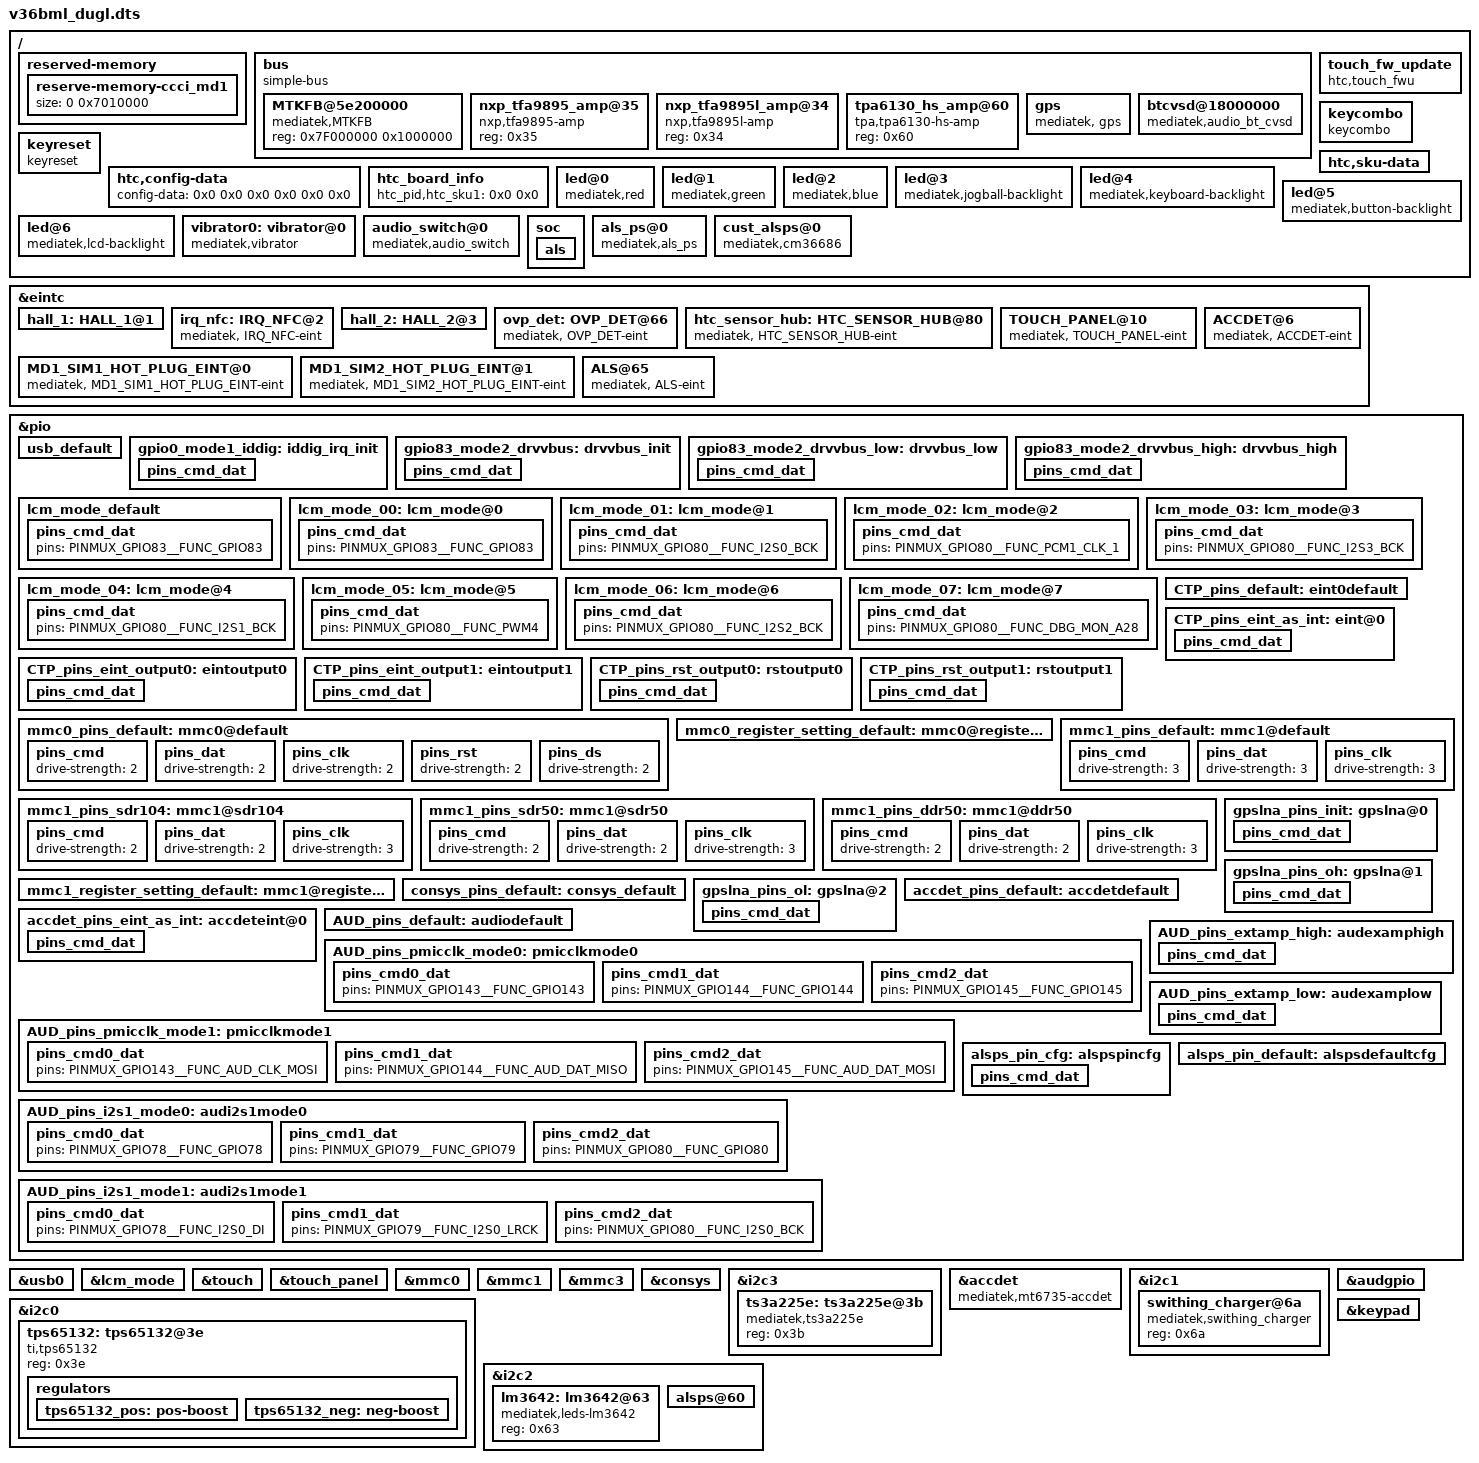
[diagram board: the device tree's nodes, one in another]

/dts-v1/;

#include "mt6753.dtsi"
#include "dt-bindings/lcm/hx8394f_hd720_dsi_vdo_truly_v36.dtsi"
/* see below #include "cust.dtsi" */

/ {
	reserved-memory {
                reserve-memory-ccci_md1 {
                        size = <0 0x7010000>;
                };
	};
        bus {
                compatible = "simple-bus";
                #address-cells = <1>;
                #size-cells = <1>;
                ranges = <0 0 0 0xffffffff>;

                MTKFB@5e200000 {
                        compatible = "mediatek,MTKFB";
                        reg = <0x7F000000 0x1000000>;
                };
                nxp_tfa9895_amp@35 {
                        compatible = "nxp,tfa9895-amp";
                        reg = <0x35>;
                };
                nxp_tfa9895l_amp@34 {
                        compatible = "nxp,tfa9895l-amp";
                        reg = <0x34>;
                };
                tpa6130_hs_amp@60 {
                        compatible = "tpa,tpa6130-hs-amp";
                        reg = <0x60>;
                };
        };
        touch_fw_update: touch_fw_update {
                compatible = "htc,touch_fwu";
        };
        keycombo {
                compatible = "keycombo";
                clr_gpio = <0x3a>;
                key_down_delay = <0x0>;
                keys_down = <0x74 0x0>;
                keys_up = <0x73 0x0>;
        };

        keyreset {
                compatible = "keyreset";
                key_down_delay = <0x2328>;
                keys_down = <0x74 0x73 0x0>;
        };
        htc,config-data {
/*        <debugflag kernelflag bootloaderflag radioflag radioflag_ex1 radioflag_ex2> */
                config-data = <0x0 0x0 0x0 0x0 0x0 0x0>;
        };

        htc,sku-data {
                sku-data = <0x0 0x0 0x0 0x0 0x0 0x0 0x0 0x0 0x0 0x0 0x0 0x0>;
        };
        htc_board_info:htc_board_info {
                htc_pid,htc_sku1 = <0x0 0x0>;
        };
/*
        ovp_det: ovp_det { };
        irq_nfc: irq_nfc { };
*/
        led@0 {
               compatible = "mediatek,red";
               led_mode = <0x0>;
               data = <0x1>;
               pwm_config = <0x0 0x0 0x0 0x0 0x0>;
        };

        led@1 {
               compatible = "mediatek,green";
               led_mode = <0x0>;
               data = <0x1>;
               pwm_config = <0x0 0x0 0x0 0x0 0x0>;
        };

        led@2 {
               compatible = "mediatek,blue";
               led_mode = <0x0>;
               data = <0x1>;
               pwm_config = <0x0 0x0 0x0 0x0 0x0>;
        };

        led@3 {
               compatible = "mediatek,jogball-backlight";
              led_mode = <0x0>;
               data = <0x1>;
             pwm_config = <0x0 0x0 0x0 0x0 0x0>;
        };

        led@4 {
               compatible = "mediatek,keyboard-backlight";
               led_mode = <0x0>;
               data = <0x1>;
               pwm_config = <0x0 0x0 0x0 0x0 0x0>;
        };

        led@5 {
               compatible = "mediatek,button-backlight";
               led_mode = <0x0>;
               data = <0x1>;
               pwm_config = <0x0 0x0 0x0 0x0 0x0>;
        };

        led@6 {
               compatible = "mediatek,lcd-backlight";
               led_mode = <0x5>;
               data = <0x1>;
               pwm_config = <0x0 0x0 0x0 0x0 0x0>;
        };
        vibrator0:vibrator@0 {
                compatible = "mediatek,vibrator";
                vib_timer = <25>;
                vib_limit = <9>;
                vib_vol= <5>;
        };
};
&eintc {
        hall_1: HALL_1@1 { };
        irq_nfc: IRQ_NFC@2 {
                                compatible = "mediatek, IRQ_NFC-eint";
                                interrupt-parent = <&eintc>;
                                interrupts = <0x2 0x4>;
                                debounce = <0x2 0x0>;
	};
        hall_2: HALL_2@3 { };
        ovp_det: OVP_DET@66 {
                                compatible = "mediatek, OVP_DET-eint";
                                interrupt-parent = <&eintc>;
                                interrupts = <0x42 0x8>;
                                debounce = <0x42 0x0>;
	 };
        htc_sensor_hub: HTC_SENSOR_HUB@80 { };
};
#include "cust.dtsi"

/* USB GPIO Kernal Standardization start */
&pio {
        usb_default: usb_default {
        };

        gpio0_mode1_iddig: iddig_irq_init {
                pins_cmd_dat {
                        pins = <PINMUX_GPIO0__FUNC_IDDIG>;
                        slew-rate = <0>;
                        bias-pull-up = <00>;
                };
        };

        gpio83_mode2_drvvbus: drvvbus_init {
                pins_cmd_dat {
                        pins = <PINMUX_GPIO83__FUNC_GPIO83>;
                        slew-rate = <1>;
                        bias-pull-up = <00>;
                };
        };

        gpio83_mode2_drvvbus_low: drvvbus_low {
                pins_cmd_dat {
                        pins = <PINMUX_GPIO83__FUNC_GPIO83>;
                        slew-rate = <1>;
                        output-low;
                        bias-pull-down = <00>;
                };
        };

        gpio83_mode2_drvvbus_high: drvvbus_high {
                pins_cmd_dat {
                        pins = <PINMUX_GPIO83__FUNC_GPIO83>;
                        slew-rate = <1>;
                        output-high;
                        bias-pull-down = <00>;
                };
        };
};

&usb0 {
        iddig_gpio = <0 1>;
        pinctrl-names = "default", "iddig_irq_init", "drvvbus_init", "drvvbus_low", "drvvbus_high";
        pinctrl-0 = <&usb_default>; /* 0x75 */
        pinctrl-1 = <&gpio0_mode1_iddig>; /* 0x76 */
        pinctrl-2 = <&gpio83_mode2_drvvbus>; /* 0x77 */
        pinctrl-3 = <&gpio83_mode2_drvvbus_low>; /* 0x78 */
        pinctrl-4 = <&gpio83_mode2_drvvbus_high>; /* 0x79 */
        status = "okay";
};
/* USB GPIO Kernal Standardization end */

/* LCM GPIO Kernal Standardization start */
&pio {
        lcm_mode_default: lcm_mode_default {
                pins_cmd_dat {
                        pins = <PINMUX_GPIO83__FUNC_GPIO83>;
                };
        };

        lcm_mode_00: lcm_mode@0 {
                pins_cmd_dat {
                        pins = <PINMUX_GPIO83__FUNC_GPIO83>;
                };
        };

        lcm_mode_01: lcm_mode@1 {
                pins_cmd_dat {
                        pins = <PINMUX_GPIO80__FUNC_I2S0_BCK>;
                };
        };

        lcm_mode_02: lcm_mode@2 {
                pins_cmd_dat {
                        pins = <PINMUX_GPIO80__FUNC_PCM1_CLK_1>;
                };
        };

        lcm_mode_03: lcm_mode@3 {
                pins_cmd_dat {
                        pins = <PINMUX_GPIO80__FUNC_I2S3_BCK>;
                };
        };

        lcm_mode_04: lcm_mode@4 {
                pins_cmd_dat {
                        pins = <PINMUX_GPIO80__FUNC_I2S1_BCK>;
                };
        };

        lcm_mode_05: lcm_mode@5 {
                pins_cmd_dat {
                        pins = <PINMUX_GPIO80__FUNC_PWM4>;
                };
        };

        lcm_mode_06: lcm_mode@6 {
                pins_cmd_dat {
                        pins = <PINMUX_GPIO80__FUNC_I2S2_BCK>;
                };
        };

        lcm_mode_07: lcm_mode@7 {
                pins_cmd_dat {
                        pins = <PINMUX_GPIO80__FUNC_DBG_MON_A28>;
                };
	};
};

&lcm_mode {
        pinctrl-names = "default", "lcm_mode_00", "lcm_mode_01", "lcm_mode_02", "lcm_mode_03", "lcm_mode_04",
         "lcm_mode_05", "lcm_mode_06", "lcm_mode_07";
        pinctrl-0 = <&lcm_mode_default>;
        pinctrl-1 = <&lcm_mode_00>;
        pinctrl-2 = <&lcm_mode_01>;
        pinctrl-3 = <&lcm_mode_02>;
        pinctrl-4 = <&lcm_mode_03>;
        pinctrl-5 = <&lcm_mode_04>;
        pinctrl-6 = <&lcm_mode_05>;
        pinctrl-7 = <&lcm_mode_06>;
        pinctrl-8 = <&lcm_mode_07>;
        lcm_power_gpio = <&pio 83 0>;
        lcm_bl_gpio = <&pio 86 0>;
        status = "okay";
};
/* LCM GPIO Kernal Standardization end */

/* TOUCH start */
&touch {
        tpd-resolution = <720 1280>;
        use-tpd-button = <0>;
        tpd-key-num = <3>;
        tpd-key-local= <139 172 158 0>;
        tpd-key-dim-local = <90 883 100 40 230 883 100 40 370 883 100 40 0 0 0 0>;
        tpd-max-touch-num = <5>;
        tpd-filter-enable = <1>;
        tpd-filter-pixel-density = <320>;
        tpd-filter-custom-prameters = <0 0 0 0 0 0 0 0 0 0 0 0>;
        tpd-filter-custom-speed = <0 0 0>;
        pinctrl-names = "default", "state_eint_as_int", "state_eint_output0", "state_eint_output1",
                "state_rst_output0", "state_rst_output1";
        pinctrl-0 = <&CTP_pins_default>;
        pinctrl-1 = <&CTP_pins_eint_as_int>;
        pinctrl-2 = <&CTP_pins_eint_output0>;
        pinctrl-3 = <&CTP_pins_eint_output1>;
        pinctrl-4 = <&CTP_pins_rst_output0>;
        pinctrl-5 = <&CTP_pins_rst_output1>;
        status = "okay";
};

&pio {
        CTP_pins_default: eint0default {
        };
        CTP_pins_eint_as_int: eint@0 {
                pins_cmd_dat {
                        pins = <PINMUX_GPIO10__FUNC_GPIO10>;
                        slew-rate = <0>;
                        bias-disable;
                };
        };
        CTP_pins_eint_output0: eintoutput0 {
                pins_cmd_dat {
                        pins = <PINMUX_GPIO10__FUNC_GPIO10>;
                        slew-rate = <1>;
                        output-low;
                };
        };
        CTP_pins_eint_output1: eintoutput1 {
                pins_cmd_dat {
                        pins = <PINMUX_GPIO10__FUNC_GPIO10>;
                        slew-rate = <1>;
                        output-high;
                };
        };
        CTP_pins_rst_output0: rstoutput0 {
                pins_cmd_dat {
                        pins = <PINMUX_GPIO62__FUNC_GPIO62>;
                        slew-rate = <1>;
                        output-low;
                };
        };
        CTP_pins_rst_output1: rstoutput1 {
                pins_cmd_dat {
                        pins = <PINMUX_GPIO62__FUNC_GPIO62>;
                        slew-rate = <1>;
                        output-high;
                };
        };
};
&touch_panel {
        interrupt-parent = <&eintc>;
        interrupts = <0xa 0x2>;
        debounce = <0xa 0x0>;
};
&eintc {
                        TOUCH_PANEL@10 {
                                compatible = "mediatek, TOUCH_PANEL-eint";
                                interrupt-parent = <&eintc>;
                                interrupts = <0xa 0x2>;
                                debounce = <0xa 0x0>;
                        };
};
/* TOUCH end */
/* mmc start */
&mmc0 {
                clk_src = /bits/ 8 <MSDC50_CLKSRC_400MHZ>;
                bus-width = <8>;
                max-frequency = <200000000>;
                cap-mmc-highspeed;
                msdc-sys-suspend;
                mmc-ddr-1_8v;
                mmc-hs200-1_8v;
                mmc-hs400-1_8v;
                non-removable;
                pinctl = <&mmc0_pins_default>;
                register_setting = <&mmc0_register_setting_default>;
                host_function = /bits/ 8 <MSDC_EMMC>;
                bootable;
                status = "okay";
};

&mmc1 {
                clk_src = /bits/ 8 <MSDC30_CLKSRC_200MHZ>;
                bus-width = <4>;
                max-frequency = <200000000>;
                msdc-sys-suspend;
                cap-sd-highspeed;
                sd-uhs-sdr12;
                sd-uhs-sdr25;
                sd-uhs-sdr50;
                sd-uhs-sdr104;
                sd-uhs-ddr50;
                pinctl = <&mmc1_pins_default>;
                pinctl_sdr104 = <&mmc1_pins_sdr104>;
                pinctl_sdr50 = <&mmc1_pins_sdr50>;
                pinctl_ddr50 = <&mmc1_pins_ddr50>;
                register_setting = <&mmc1_register_setting_default>;
                host_function = /bits/ 8 <MSDC_SD>;
                cd_level = /bits/ 8 <MSDC_CD_LOW>;
                cd-gpios = <&pio 5 0>;
                status = "okay";
};

&mmc3 {
                clk_src = /bits/ 8 <MSDC30_CLKSRC_200MHZ>;
                bus-width = <4>;
                max-frequency = <50000000>;
                cap-sd-highspeed;
                sd-uhs-sdr12;
                sd-uhs-sdr25;
                sd-uhs-sdr50;
                host_function = /bits/ 8 <MSDC_SDIO>;
                non-removable;
                status = "okay";
};

&pio {
        mmc0_pins_default: mmc0@default {
                        pins_cmd {
                                drive-strength = /bits/ 8 <2>;
                        };
                        pins_dat {
                                drive-strength = /bits/ 8 <2>;
                        };
                        pins_clk {
                                drive-strength = /bits/ 8 <2>;
                        };
                        pins_rst {
                                drive-strength = /bits/ 8 <2>;
                        };
                        pins_ds {
                                drive-strength = /bits/ 8 <2>;
                        };
        };

        mmc0_register_setting_default: mmc0@register_default {
                dat0rddly      = /bits/ 8 <0>;
                dat1rddly      = /bits/ 8 <0>;
                dat2rddly      = /bits/ 8 <0>;
                dat3rddly      = /bits/ 8 <0>;
                dat4rddly      = /bits/ 8 <0>;
                dat5rddly      = /bits/ 8 <0>;
                dat6rddly      = /bits/ 8 <0>;
                dat7rddly      = /bits/ 8 <0>;
                datwrddly      = /bits/ 8 <0>;
                cmdrrddly      = /bits/ 8 <0>;
                cmdrddly       = /bits/ 8 <0>;
                cmd_edge = /bits/ 8 <MSDC_SMPL_FALLING>;
                rdata_edge = /bits/ 8 <MSDC_SMPL_FALLING>;
                wdata_edge = /bits/ 8 <MSDC_SMPL_FALLING>;

                ett-hs200-cells = <12>;
                ett-hs200-default = <OFFSET_MSDC_PATCH_BIT0     MSDC_PB0_INT_DAT_LATCH_CK_SEL 0x0
                        OFFSET_MSDC_PATCH_BIT0  MSDC_PB0_CKGEN_MSDC_DLY_SEL   0x0
                        OFFSET_MSDC_PATCH_BIT1  MSDC_PB1_CMD_RSP_TA_CNTR      0x1
                        OFFSET_MSDC_IOCON               MSDC_IOCON_RSPL               0x1
                        OFFSET_MSDC_PAD_TUNE0   MSDC_PAD_TUNE0_CMDRDLY        0xf
                        OFFSET_MSDC_PAD_TUNE0   MSDC_PAD_TUNE0_CMDRRDLY       0x0
                        OFFSET_MSDC_PATCH_BIT1          MSDC_PB1_WRDAT_CRCS_TA_CNTR   0x1
                        OFFSET_MSDC_PAD_TUNE0   MSDC_PAD_TUNE0_DATWRDLY       0xf
                        OFFSET_MSDC_IOCON                       MSDC_IOCON_W_D0SPL            0x1
                        OFFSET_MSDC_DAT_RDDLY0          MSDC_DAT_RDDLY0_D0            0xf
                        OFFSET_MSDC_PAD_TUNE0   MSDC_PAD_TUNE0_DATRRDLY       0x16
                        OFFSET_MSDC_IOCON               MSDC_IOCON_R_D_SMPL           0x0>;

                ett-hs400-cells = <8>;
                ett-hs400-default = <OFFSET_MSDC_PATCH_BIT0     MSDC_PB0_INT_DAT_LATCH_CK_SEL   0x0
                        OFFSET_MSDC_PATCH_BIT0          MSDC_PB0_CKGEN_MSDC_DLY_SEL             0x0
                        OFFSET_EMMC50_PAD_DS_TUNE       MSDC_EMMC50_PAD_DS_TUNE_DLY1    0x2
                        OFFSET_EMMC50_PAD_DS_TUNE       MSDC_EMMC50_PAD_DS_TUNE_DLY3    0xe
                        OFFSET_MSDC_PATCH_BIT1                  MSDC_PB1_CMD_RSP_TA_CNTR        0x1
                        OFFSET_MSDC_IOCON               MSDC_IOCON_RSPL                         0x0
                        OFFSET_MSDC_PAD_TUNE0                   MSDC_PAD_TUNE0_CMDRDLY          0xf
                        OFFSET_MSDC_PAD_TUNE0           MSDC_PAD_TUNE0_CMDRRDLY         0xd>;
        };

        mmc1_pins_default: mmc1@default {
                        pins_cmd {
                                drive-strength = /bits/ 8 <3>;
                        };
                        pins_dat {
                                drive-strength = /bits/ 8 <3>;
                        };
                        pins_clk {
                                drive-strength = /bits/ 8 <3>;
                        };
        };

        mmc1_pins_sdr104: mmc1@sdr104 {
                        pins_cmd {
                                drive-strength = /bits/ 8 <2>;
                        };
                        pins_dat {
                                drive-strength = /bits/ 8 <2>;
                        };
                        pins_clk {
                                drive-strength = /bits/ 8 <3>;
                        };
        };

        mmc1_pins_sdr50: mmc1@sdr50 {
                        pins_cmd {
                                drive-strength = /bits/ 8 <2>;
                        };
                        pins_dat {
                                drive-strength = /bits/ 8 <2>;
                        };
                        pins_clk {
                                drive-strength = /bits/ 8 <3>;
                        };
        };

        mmc1_pins_ddr50: mmc1@ddr50 {
                        pins_cmd {
                                drive-strength = /bits/ 8 <2>;
                        };
                        pins_dat {
                                drive-strength = /bits/ 8 <2>;
                        };
                        pins_clk {
                                drive-strength = /bits/ 8 <3>;
                        };
        };

        mmc1_register_setting_default: mmc1@register_default {
                                dat0rddly      = /bits/ 8 <0>;
                                dat1rddly      = /bits/ 8 <0>;
                                dat2rddly      = /bits/ 8 <0>;
                                dat3rddly      = /bits/ 8 <0>;
                                datwrddly      = /bits/ 8 <0>;
                                cmdrrddly      = /bits/ 8 <0>;
                                cmdrddly       = /bits/ 8 <0>;
                                cmd_edge = /bits/ 8 <MSDC_SMPL_FALLING>;
                                rdata_edge = /bits/ 8 <MSDC_SMPL_FALLING>;
                                wdata_edge = /bits/ 8 <MSDC_SMPL_FALLING>;
        };
};
/* mmc end */

/* CONSYS GPIO standardization */
&pio {
        consys_pins_default: consys_default {

        };

        gpslna_pins_init: gpslna@0 {

            pins_cmd_dat {
                        pins = <PINMUX_GPIO64__FUNC_GPIO64>;
                        slew-rate = <0>;
                        bias-disable;
                        output-low;
                };
        };

        gpslna_pins_oh: gpslna@1 {

            pins_cmd_dat {
                        pins = <PINMUX_GPIO64__FUNC_GPIO64>;
                        slew-rate = <1>;
                        output-high;
                };
        };

        gpslna_pins_ol: gpslna@2 {

            pins_cmd_dat {
                        pins = <PINMUX_GPIO64__FUNC_GPIO64>;
                        slew-rate = <1>;
                        output-low;
                };
        };

};

/ {
	bus {
		gps {
			compatible = "mediatek, gps", "mediatek, mt3326-gps";
		};
	};
};
&consys {
        pinctrl-names = "default", "gps_lna_state_init", "gps_lna_state_oh", "gps_lna_state_ol";
        pinctrl-0 = <&consys_pins_default>;
        pinctrl-1 = <&gpslna_pins_init>;
        pinctrl-2 = <&gpslna_pins_oh>;
        pinctrl-3 = <&gpslna_pins_ol>;
        status = "okay";

};
/* CONSYS end */
/* wifi/bt */
/ {
        bus {
                /delete-node/ btcvsd@10000000;
                btcvsd@18000000 {
                        compatible = "mediatek,audio_bt_cvsd";
                        reg = <0x18000000 0x1000 0x18080000 0x1000>;
                        interrupts = <0x0 0xe6 0x8>;
                };
        };
};

/* headphones */
/ {
  audio_switch@0 {
   compatible = "mediatek,audio_switch";
  };
};
&eintc {
	ACCDET@6{
	    compatible = "mediatek, ACCDET-eint";
	    interrupt-parent = <&eintc>;
	    interrupts = <6 8>;
	    debounce = <6 256000>;
	};
};
&pio{
    accdet_pins_default: accdetdefault{
    };
    accdet_pins_eint_as_int: accdeteint@0 {
        pins_cmd_dat {
            pins = <PINMUX_GPIO6__FUNC_GPIO6>;
            slew-rate = <0>;
            bias-disable;
        };
    };
};
&i2c3 {
	ts3a225e:ts3a225e@3b {
		compatible = "mediatek,ts3a225e";
		reg = <0x3b>;
		status = "okay";
	};
};
&accdet {
		compatible = "mediatek,mt6735-accdet", "mediatek,mt6735m-accdet", "mediatek,mt6753-accdet";
/* try later
        accdet-mic-vol = <7>;//mic電壓2.5v
        headset-mode-setting = <0x500 0x200 1 0x1F0 0x800 0x800 0x20>;
        accdet-plugout-debounce = <20>;//拔出耳機去抖時間間隔
*/
        /*1:ACC mode, 2:low cost without in bias, 6:low cost with in bias*/
/*
        accdet-mic-mode = <1>;
*/
        /*0--MD_MAX--UP_MAX--DW_MAX*/
        /*
        三段式耳機(MID/UP/DOWN PMIC內部通過AUXADC采樣)檢測電壓范圍(mV)
        0<= Vol < 80: MID
        80<= Vol < 228: UP
        228<= Vol < 500: DOWN
        */
/*
        headset-three-key-threshold = <0 80 220 500>;
*/
        /*0--MD_MAX--VOICE_MAX--UP_MAX--DW_MAX*/
        /*
        四段式耳機(MID/VOICE/UP/DOWN PMIC內部通過AUXADC采樣)檢測電壓范圍(mV)
        0<= Vol < 58: MID
        58<= Vol < 121: VOICE
        121<= Vol < 192: UP
        192<= Vol < 450: DOWN
        */
/*
        headset-four-key-threshold = <0 58 121 192 450>;
*/
                accdet-mic-vol = <7>;
                headset-mode-setting = <0x500 0x200 1 0x1F0 0x800 0x800 0x20>;
                accdet-plugout-debounce = <20>;
                /*1:ACC mode, 2:low cost without in bias, 6:low cost with in bias*/
                accdet-mic-mode = <6>;
                /*0--MD_MAX--UP_MAX--DW_MAX*/
                headset-three-key-threshold = <0 80 220 500>;
                headset-three-key-threshold-CDD = <0 178 283 600>;
                /*0--MD_MAX--VOICE_MAX--UP_MAX--DW_MAX*/
                headset-four-key-threshold = <0 58 121 192 450>;
        pinctrl-names = "default", "state_eint_as_int";
        pinctrl-0 = <&accdet_pins_default>;
        pinctrl-1 = <&accdet_pins_eint_as_int>;
        status = "okay";
};
/*
/ {
	soc {
		accdet {
			        compatible = "mediatek, ACCDET-eint";
                                interrupt-parent = <&eintc>;
                                interrupts = <0x6 0x8>;
                                debounce = <0x6 0x3e800>;
		};
	};
};
*/

/* bq24158 power charger */
&i2c1 {
	swithing_charger@6a {
		compatible = "mediatek,swithing_charger";
		reg = <0x6a>;
		status = "okay";
	};
};

/* tps65132 pmic */
&i2c0 {
	tps65132:tps65132@3e {
        	compatible = "ti,tps65132";
	        reg = <0x3e>;

/*        	i2c-pwr-supply = <&regulators_supply>; */
	        regulators {
        	        tps65132_pos: pos-boost {
	                        regulator-name  = "tps65132_pos";
                        	regulator-min-microvolt = <5400000>;
                	        regulator-max-microvolt = <5400000>;
        	                ti,discharge-enable;
	                        ti,enable-time = <800>;
                        	ti,current-limit = <200000>;
                	        ti,en-gpio = <&pio 97 0>;
        	        };

	                tps65132_neg: neg-boost {
                	        regulator-name = "tps65132_neg";
        	                regulator-min-microvolt = <5400000>;
	                        regulator-max-microvolt = <5400000>;
                	        ti,discharge-enable;
        	                ti,enable-time = <800>;
	                        ti,current-limit = <40000>;
                        	ti,en-gpio = <&pio 32 0>;
                	};
        	};

	};
};

/* leds-lcm3642 */
&i2c2 {
	/delete-node/ strobe_main@63;
	lm3642:lm3642@63 {
		compatible = "mediatek,leds-lm3642";
		reg = <0x63>;
	};
};

/* SENtral sensor hub and sensors: ak8789, bma253, cm36686 */
&htc_sensor_hub {
                                compatible = "mediatek, HTC_SENSOR_HUB-eint";
                                interrupt-parent = <&eintc>;
                                interrupts = <0x50 0x4>;
                                debounce = <0x50 0x0>;
                        };
/* bma253 accelometer */
/*

&i2c2 {
	bma253: g_sensor_bma253@18 {
                compatible = "htc_g_sensor,bma253_bosch";
                reg = <0x18>;
                g_sensor_bma253,intr = <0x0>;
                g_sensor_bma253,chip_layout = <0x4>;
                g_sensor_bma253,axis_map_x = <0x0>;
                g_sensor_bma253,axis_map_y = <0x1>;
                g_sensor_bma253,axis_map_z = <0x2>;
                g_sensor_bma253,negate_x = <0x1>;
                g_sensor_bma253,negate_y = <0x1>;
                g_sensor_bma253,negate_z = <0x0>;
        };
};
*/
/* ak8789 */
/*
/ {
        hall_ak8789 {
                compatible = "hall_sensor,ak8789";
                hall,att_used = <0x2>;
                hall,att_gpio = <0x3>;
                hall,att_gpio_s = <0x1>;
        };
};
                        &hall_1 {
                                compatible = "mediatek, HALL_1-eint";
                                interrupt-parent = <&eintc>;
                                interrupts = <0x1 0x8>;
                                debounce = <0x1 0x0>;
                        };
                        &hall_2 {
                                compatible = "mediatek, HALL_2-eint";
                                interrupt-parent = <&eintc>;
                                interrupts = <0x3 0x8>;
                                debounce = <0x3 0x0>;
                        };
*/
/* cm3886 proximity alsps */
/* see sensor hub */
/*
&i2c2 {
			/delete-node/ alsps@60;
                        cm36686@60 {
                                compatible = "CM36686","mediatek,alsps";
                                reg = <0x60>;
                                cm36686,irq-gpio = <0x4>;
                                cm36686,engineer-id = <0x0>;
                                cm36686,levels = <0x3 0xa 0x10 0x4e 0x9e 0x422 0x633 0xb29 0xf4c 0x0>;
                                cm36686,levels_2 = <0x3 0xa 0x10 0x4e 0x9e 0x422 0x633 0xb29 0xf4c 0x0>;
                                cm36686,golden_adc = <0x399>;
                                cm36686,golden_adc_2 = <0x399>;
                                cm36686,cm36686_slave_address = <0x60>;
                                cm36686,ps1_thd_set = <0x15>;
                                cm36686,ps1_thd_no_cal = <0x5f>;
                                cm36686,dynamical_threshold = <0x1>;
                                cm36686,dark_level = <0x3>;
                                cm36686,ps_duty = <0x0>;
                                cm36686,ps_pers = <0x1>;
                                cm36686,ps_it = <0x7>;
                                cm36686,ps_hd = <0x0>;
                                cm36686,ps_led_current = <0x2>;
                                status = "okay";
                                pinctrl-names = "pin_default", "pin_cfg";
                                pinctrl-0 = <&alsps_pin_default>;
                                pinctrl-1 = <&alsps_pin_cfg>;
                        };
};
*/
/*
/{
als_ps@0 {
                        compatible = "mediatek,als_ps";
                        pinctrl-names = "pin_default", "pin_cfg";
                        pinctrl-0 = <&alsps_pin_default>;
                        pinctrl-1 = <&alsps_pin_cfg>;
                        status = "okay";
	};
};
&pio {
                        alsps_pin_cfg: alspspincfg {
                                pins_cmd_dat {
                                        pins = <0x400>;
                                        slew-rate = <0x0>;
                                        bias-pull-up = <0x0>;
                                };
                        };

                        alsps_pin_default: alspsdefaultcfg {
                        };
};

&i2c2{
                        alsps@60 {
                                compatible = "mediatek,alsps";
                                reg = <0x60>;
                                status = "okay";
                                pinctrl-names = "pin_default", "pin_cfg";
                                pinctrl-0 = <&alsps_pin_default>;
                                pinctrl-1 = <&alsps_pin_cfg>;
                        };
};
*/

&audgpio {
/*        pinctrl-names = "default", "audpmicclk-mode0", "audpmicclk-mode1", "audi2s1-mode0", "audi2s1-mode1", "extamp-pullhigh", "extamp-pulllow", "extamp2-pullhigh", "extamp2-pulllow", "rcvspk-pullhigh", "rcvspk-pulllow";
*/
        pinctrl-names = "default", "audpmicclk-mode0", "audpmicclk-mode1", "audi2s1-mode0", "audi2s1-mode1", "extamp-pullhigh", "extamp-pulllow";
        pinctrl-0 = <&AUD_pins_default>;
        pinctrl-1 = <&AUD_pins_pmicclk_mode0>;
        pinctrl-2 = <&AUD_pins_pmicclk_mode1>;
        pinctrl-3 = <&AUD_pins_i2s1_mode0>;
        pinctrl-4 = <&AUD_pins_i2s1_mode1>;
        pinctrl-5 = <&AUD_pins_extamp_high>;
        pinctrl-6 = <&AUD_pins_extamp_low>;
/*        pinctrl-7 = <&AUD_pins_extamp2_high>;
        pinctrl-8 = <&AUD_pins_extamp2_low>;
        pinctrl-9 = <&AUD_pins_rcvspk_high>;
        pinctrl-10 = <&AUD_pins_rcvspk_low>;
*/        extspkamp-gpio = <21 0>;
        status = "okay";
};
&pio {
        AUD_pins_default: audiodefault {
        };
        AUD_pins_pmicclk_mode0: pmicclkmode0 {
                pins_cmd0_dat {
                        pins = <PINMUX_GPIO143__FUNC_GPIO143>;
                };
                pins_cmd1_dat {
                        pins = <PINMUX_GPIO144__FUNC_GPIO144>;
                };
                pins_cmd2_dat {
                        pins = <PINMUX_GPIO145__FUNC_GPIO145>;
                };
        };
        AUD_pins_pmicclk_mode1: pmicclkmode1 {
                pins_cmd0_dat {
                        pins = <PINMUX_GPIO143__FUNC_AUD_CLK_MOSI>;
                };
                pins_cmd1_dat {
                        pins = <PINMUX_GPIO144__FUNC_AUD_DAT_MISO>;
                };
                pins_cmd2_dat {
                        pins = <PINMUX_GPIO145__FUNC_AUD_DAT_MOSI>;
                };
        };
        AUD_pins_i2s1_mode0: audi2s1mode0 {
                pins_cmd0_dat {
                        pins = <PINMUX_GPIO78__FUNC_GPIO78>;
                };
                pins_cmd1_dat {
                        pins = <PINMUX_GPIO79__FUNC_GPIO79>;
                };
                pins_cmd2_dat {
                        pins = <PINMUX_GPIO80__FUNC_GPIO80>;
                };
        };
        AUD_pins_i2s1_mode1: audi2s1mode1 {
                pins_cmd0_dat {
                        pins = <PINMUX_GPIO78__FUNC_I2S0_DI>;
                };
                pins_cmd1_dat {
                        pins = <PINMUX_GPIO79__FUNC_I2S0_LRCK>;
                };
                pins_cmd2_dat {
                        pins = <PINMUX_GPIO80__FUNC_I2S0_BCK>;
                };
        };
        AUD_pins_extamp_high: audexamphigh {
                pins_cmd_dat {
                        pins = <PINMUX_GPIO21__FUNC_GPIO21>;
                                slew-rate = <1>;
                                bias-pull-down = <1>;
                                output-high;
                };
        };
        AUD_pins_extamp_low: audexamplow {
                pins_cmd_dat {
                        pins = <PINMUX_GPIO21__FUNC_GPIO21>;
                                slew-rate = <1>;
                                bias-pull-down = <1>;
                                output-low;
                };
        };
/*
        AUD_pins_extamp2_high: audexam2phigh {
                pins_cmd_dat {
                        pins = <PINMUX_GPIO21__FUNC_GPIO21>;
                                slew-rate = <1>;
                                bias-pull-down = <1>;
                                output-high;
                };
        };
        AUD_pins_extamp2_low: audexamp2low {
                pins_cmd_dat {
                        pins = <PINMUX_GPIO21__FUNC_GPIO21>;
                                slew-rate = <1>;
                                bias-pull-down = <1>;
                                output-low;
                };
        };
        AUD_pins_rcvspk_high: audrcvspkhigh {
                pins_cmd_dat {
                        pins = <PINMUX_GPIO120__FUNC_GPIO120>;
                                slew-rate = <1>;
                                output-high;
                };
        };
        AUD_pins_rcvspk_low: audrcvspklow {
                pins_cmd_dat {
                        pins = <PINMUX_GPIO120__FUNC_GPIO120>;
                                slew-rate = <1>;
                                output-low;
                };
        };
*/
};
/* AUDIO end */

/* in fact we can just return the deafult codegen.dws which i broken
to make keypad work without such a hack */
&keypad {
        mediatek,kpd-hw-init-map = <114 114 0 0 0 0 0 0 0 0 0 0 0 0 0 0 0 0 0 0 0 0 0 0 
                                0 0 0 0 0 0 0 0 0 0 0 0 0 0 0 0 0 0 0 0 0 0 0 0 
                                0 0 0 0 0 0 0 0 0 0 0 0 0 0 0 0 0 0 0 0 0 0 0 0 >;
};

/* SIM card pins */
&eintc{
	MD1_SIM1_HOT_PLUG_EINT@0 {
        	compatible = "mediatek, MD1_SIM1_HOT_PLUG_EINT-eint";
	        interrupts = <0 8>;
        	debounce = <0 100000>;
	        dedicated = <0 0>;
        	src_pin = <0 1>;
	        sockettype=<0 1>;
	};

	MD1_SIM2_HOT_PLUG_EINT@1 {
        	compatible = "mediatek, MD1_SIM2_HOT_PLUG_EINT-eint";
	        interrupts = <1 8>;
        	debounce = <1 100000>;
	        dedicated = <1 0>;
        	src_pin = <1 2>;
	        sockettype=<1 1>;
	};
};
/* end sim card pins */
/* cm36686-new driver */
&pio {
                        alsps_pin_cfg: alspspincfg {
                                pins_cmd_dat {
                                        pins = <0x400>;
                                        slew-rate = <0x0>;
                                        bias-pull-up = <0x0>;
                                };
                        };

                        alsps_pin_default: alspsdefaultcfg {
                        };
};

&eintc {
	ALS@65 {
                                compatible = "mediatek, ALS-eint";
                                interrupts = <0x41 0x8>;
                                debounce = <0x41 0x0>;		
                        pinctrl-names = "pin_default", "pin_cfg", "default", "cfg";
                        pinctrl-0 = <&alsps_pin_default>;
                        pinctrl-1 = <&alsps_pin_cfg>;
                        pinctrl-2 = <&alsps_pin_default>;
                        pinctrl-3 = <&alsps_pin_cfg>;
	};
};

&i2c2{
	alsps@60 {
                        pinctrl-names = "pin_default", "pin_cfg", "default", "cfg";
                        pinctrl-0 = <&alsps_pin_default>;
                        pinctrl-1 = <&alsps_pin_cfg>;
                        pinctrl-2 = <&alsps_pin_default>;
                        pinctrl-3 = <&alsps_pin_cfg>;
	};
};
/ {
	soc {
		als {
                                interrupts = <0x41 0x8>;
                                debounce = <0x41 0x0>;		

		};
	};
	als_ps@0 {
                        compatible = "mediatek,als_ps";
                        pinctrl-names = "pin_default", "pin_cfg", "default", "cfg";
                        pinctrl-0 = <&alsps_pin_default>;
                        pinctrl-1 = <&alsps_pin_cfg>;
                        pinctrl-2 = <&alsps_pin_default>;
                        pinctrl-3 = <&alsps_pin_cfg>;
                        status = "okay";
	};
	cust_alsps@0 {
                compatible = "mediatek,cm36686";
                i2c_num = <0x2>;
                i2c_addr = <0x60 0x0 0x0 0x0>;
                polling_mode_ps = <0x0>;
                polling_mode_als = <0x1>;
                power_id = <0xffff>;
                power_vol = <0x0>;
/* default
                als_level = <0x0 0x101 0x27d 0x403 0x8f9 0x15d4 0x1a4a 0x2c25 0x4fe1 0x64a8 0x7992 0xb1f0 0xe251 0xe251 0xe251>;
                als_value = <0x0 0x84 0x130 0x1f6 0x3ec 0x7d3 0xbbe 0x138e 0x1f44 0x2710 0x2ee0 0x3e80 0x4e20 0x4e20 0x4e20 0x4e20>;
*/
		/* Total has 15 level*/
		als_level = <0x3 0xa 0x10 0x4e 0x9e 0x422 0x633 0xb29 0xf4c 0x0 0x0 0x0 0x0 0x0 0x0>;
		/*  Total has 16 range*/
		als_value = <0 4 10 16 75 150 1000 1500 2700 4070 0 0 0 0 0 0>;
/*		als_value = <0x0 0x3 0xa 0x10 0x4e 0x9e 0x422 0x633 0xb29 0xf4c 0x0 0x0 0x0 0x0 0x0 0x0>; */
                ps_threshold_high = <0x46>;
                ps_threshold_low = <0x28>; 
/* old driver
		ps_threshold_high = <0x5f>;
                ps_threshold_low = <0x15>;
*/
		ps_threshold_high	=  <70>;
		ps_threshold_low	=  <40>;
                is_batch_supported_ps = <0x1>;
                is_batch_supported_als = <0x1>;
                pinctrl-names = "pin_default", "pin_cfg", "default", "cfg";
                pinctrl-0 = <&alsps_pin_default>;
                pinctrl-1 = <&alsps_pin_cfg>;
                pinctrl-2 = <&alsps_pin_default>;
                pinctrl-3 = <&alsps_pin_cfg>;
		interrupt-parent = <&eintc>;
                interrupts = <0x41 0x8>;
                debounce = <0x41 0x0>;		
	};
};
/* end cm36686-new driver */
/* END OF THE */
#include "v36bml_touchpad.dtsi"
/* #include "v36bml/cust.dtsi" */
/* DTS FILE */

